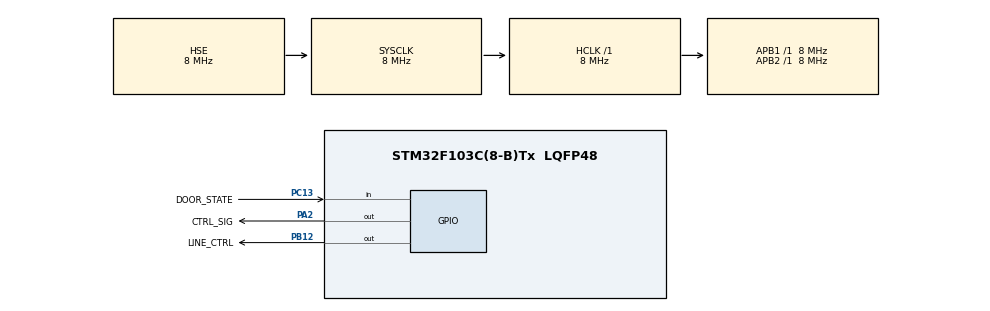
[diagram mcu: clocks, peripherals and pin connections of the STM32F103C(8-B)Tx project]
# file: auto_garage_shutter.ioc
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Mcu.Family=STM32F1
Mcu.Name=STM32F103C(8-B)Tx
Mcu.Package=LQFP48
NVIC.PriorityGroup=NVIC_PRIORITYGROUP_4
PA13.Mode=Serial_Wire
PA13.Signal=SYS_JTMS-SWDIO
PA14.Mode=Serial_Wire
PA14.Signal=SYS_JTCK-SWCLK
PA2.GPIO_Label=CTRL_SIG
PA2.Signal=GPIO_Output
PB12.GPIO_Label=LINE_CTRL
PB12.Signal=GPIO_Output
PC13-TAMPER-RTC.GPIO_Label=DOOR_STATE
PC13-TAMPER-RTC.Signal=GPIO_Input
PD0-OSC_IN.Mode=HSE-External-Oscillator
PD0-OSC_IN.Signal=RCC_OSC_IN
PD1-OSC_OUT.Mode=HSE-External-Oscillator
PD1-OSC_OUT.Signal=RCC_OSC_OUT
ProjectManager.HeapSize=0x200
ProjectManager.StackSize=0x400
ProjectManager.TargetToolchain=STM32CubeIDE
RCC.AHBFreq_Value=8000000
RCC.APB1Freq_Value=8000000
RCC.APB1TimFreq_Value=8000000
RCC.APB2Freq_Value=8000000
RCC.APB2TimFreq_Value=8000000
RCC.HCLKFreq_Value=8000000
RCC.PLLSourceVirtual=RCC_PLLSOURCE_HSE
RCC.RTCClockSelection=RCC_RTCCLKSOURCE_HSE_DIV128
RCC.SYSCLKFreq_VALUE=8000000
RCC.SYSCLKSource=RCC_SYSCLKSOURCE_HSE
RCC.USBFreq_Value=16000000
VP_RTC_VS_RTC_Activate.Mode=RTC_Enabled
board=custom

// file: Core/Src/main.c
/* USER CODE BEGIN Header */
/**
  ******************************************************************************
  * @file           : main.c
  * @brief          : Main program body
  ******************************************************************************
  * @attention
  *
  * Copyright (c) 2025 STMicroelectronics.
  * All rights reserved.
  *
  * This software is licensed under terms that can be found in the LICENSE file
  * in the root directory of this software component.
  * If no LICENSE file comes with this software, it is provided AS-IS.
  *
  ******************************************************************************
  */
/* USER CODE END Header */
#include "main.h"

RTC_HandleTypeDef hrtc;

/* USER CODE BEGIN PV */
static const uint16_t IMPULS_LEN_DOOR_CLOSE = 700;

/* USER CODE END PV */

void SystemClock_Config(void);
static void MX_GPIO_Init(void);
static void MX_RTC_Init(void);
/* USER CODE BEGIN PFP */
bool doorOpen(void);
void closeDoor(void);
void shutDown(void);
void gotoSleep(void);
/* USER CODE END PFP */

int main(void)
{

  /* MCU Configuration--------------------------------------------------------*/

  /* Reset of all peripherals, Initializes the Flash interface and the Systick. */
  HAL_Init();

  /* Configure the system clock */
  SystemClock_Config();

  /* Initialize all configured peripherals */
  MX_GPIO_Init();
  MX_RTC_Init();

  /* Infinite loop */
  /* USER CODE BEGIN WHILE */
  while (1)
  {
	if(doorOpen() == true) {

		gotoSleep();

		if(doorOpen() == true) {
			closeDoor();
		}

	}

	shutDown();
    /* USER CODE END WHILE */

  }
}

void SystemClock_Config(void)
{
  RCC_OscInitTypeDef RCC_OscInitStruct = {0};
  RCC_ClkInitTypeDef RCC_ClkInitStruct = {0};
  RCC_PeriphCLKInitTypeDef PeriphClkInit = {0};

  /** Initializes the RCC Oscillators according to the specified parameters
  * in the RCC_OscInitTypeDef structure.
  */
  RCC_OscInitStruct.OscillatorType = RCC_OSCILLATORTYPE_HSE;
  RCC_OscInitStruct.HSEState = RCC_HSE_ON;
  RCC_OscInitStruct.PLL.PLLState = RCC_PLL_NONE;
  if (HAL_RCC_OscConfig(&RCC_OscInitStruct) != HAL_OK)
  {
    Error_Handler();
  }

  /** Initializes the CPU, AHB and APB buses clocks
  */
  RCC_ClkInitStruct.ClockType = RCC_CLOCKTYPE_HCLK|RCC_CLOCKTYPE_SYSCLK
                              |RCC_CLOCKTYPE_PCLK1|RCC_CLOCKTYPE_PCLK2;
  RCC_ClkInitStruct.SYSCLKSource = RCC_SYSCLKSOURCE_HSE;
  RCC_ClkInitStruct.AHBCLKDivider = RCC_SYSCLK_DIV1;
  RCC_ClkInitStruct.APB1CLKDivider = RCC_HCLK_DIV1;
  RCC_ClkInitStruct.APB2CLKDivider = RCC_HCLK_DIV1;

  if (HAL_RCC_ClockConfig(&RCC_ClkInitStruct, FLASH_LATENCY_0) != HAL_OK)
  {
    Error_Handler();
  }
  PeriphClkInit.PeriphClockSelection = RCC_PERIPHCLK_RTC;
  PeriphClkInit.RTCClockSelection = RCC_RTCCLKSOURCE_HSE_DIV128;
  if (HAL_RCCEx_PeriphCLKConfig(&PeriphClkInit) != HAL_OK)
  {
    Error_Handler();
  }
}

static void MX_RTC_Init(void)
{

  /** Initialize RTC Only
  */
  hrtc.Instance = RTC;
  hrtc.Init.AsynchPrediv = RTC_AUTO_1_SECOND;
  hrtc.Init.OutPut = RTC_OUTPUTSOURCE_ALARM;
  if (HAL_RTC_Init(&hrtc) != HAL_OK)
  {
    Error_Handler();
  }

}

static void MX_GPIO_Init(void)
{
  GPIO_InitTypeDef GPIO_InitStruct = {0};

  /* GPIO Ports Clock Enable */
  __HAL_RCC_GPIOC_CLK_ENABLE();
  __HAL_RCC_GPIOD_CLK_ENABLE();
  __HAL_RCC_GPIOA_CLK_ENABLE();
  __HAL_RCC_GPIOB_CLK_ENABLE();

  /*Configure GPIO pin Output Level */
  HAL_GPIO_WritePin(CTRL_SIG_GPIO_Port, CTRL_SIG_Pin, GPIO_PIN_RESET);

  /*Configure GPIO pin Output Level */
  HAL_GPIO_WritePin(LINE_CTRL_GPIO_Port, LINE_CTRL_Pin, GPIO_PIN_RESET);

  /*Configure GPIO pin : DOOR_STATE_Pin */
  GPIO_InitStruct.Pin = DOOR_STATE_Pin;
  GPIO_InitStruct.Mode = GPIO_MODE_INPUT;
  GPIO_InitStruct.Pull = GPIO_NOPULL;
  HAL_GPIO_Init(DOOR_STATE_GPIO_Port, &GPIO_InitStruct);

  /*Configure GPIO pin : CTRL_SIG_Pin */
  GPIO_InitStruct.Pin = CTRL_SIG_Pin;
  GPIO_InitStruct.Mode = GPIO_MODE_OUTPUT_PP;
  GPIO_InitStruct.Pull = GPIO_NOPULL;
  GPIO_InitStruct.Speed = GPIO_SPEED_FREQ_LOW;
  HAL_GPIO_Init(CTRL_SIG_GPIO_Port, &GPIO_InitStruct);

  /*Configure GPIO pin : LINE_CTRL_Pin */
  GPIO_InitStruct.Pin = LINE_CTRL_Pin;
  GPIO_InitStruct.Mode = GPIO_MODE_OUTPUT_PP;
  GPIO_InitStruct.Pull = GPIO_NOPULL;
  GPIO_InitStruct.Speed = GPIO_SPEED_FREQ_LOW;
  HAL_GPIO_Init(LINE_CTRL_GPIO_Port, &GPIO_InitStruct);

}

/* USER CODE BEGIN 4 */
void shutDown(void) {
	HAL_GPIO_WritePin(CTRL_SIG_GPIO_Port, CTRL_SIG_Pin, GPIO_PIN_SET);
	HAL_Delay(100);
}

bool doorOpen(void) {
	if(HAL_GPIO_ReadPin(DOOR_STATE_GPIO_Port, DOOR_STATE_Pin) == false) {
		return true;
	}

	return false;
}

void closeDoor(void) {
	HAL_GPIO_WritePin(LINE_CTRL_GPIO_Port, LINE_CTRL_Pin, GPIO_PIN_SET);
	HAL_Delay(IMPULS_LEN_DOOR_CLOSE);
	HAL_GPIO_WritePin(LINE_CTRL_GPIO_Port, LINE_CTRL_Pin, GPIO_PIN_RESET);
}

void gotoSleep(void) {

}
/* USER CODE END 4 */

void Error_Handler(void)
{
  __disable_irq();
  while (1)
  {
  }
}
